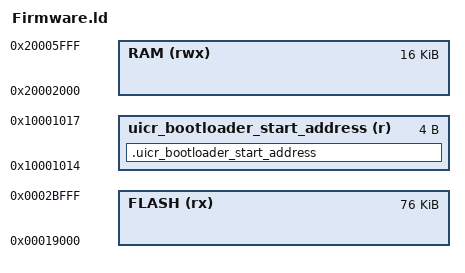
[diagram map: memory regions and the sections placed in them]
/* Linker script to configure memory regions. */

SEARCH_DIR(.)
GROUP(-lgcc -lc -lnosys)

/* More info about the memory layout here: */
/* https://infocenter.nordicsemi.com/topic/sdk_nrf5_v17.0.0/lib_bootloader.html#lib_bootloader_memory */
MEMORY
{
  /* We have 192 KB Flash (0x30000), 24 KB RAM (0x6000) */
  /* Softdevice uses pages from 0x0 to 0x18000 included */
  FLASH (rx) : ORIGIN = 0x19000, LENGTH = 0x13000 /* Total = 0x2C000 => max available memory in debug */
  RAM (rwx) :  ORIGIN = 0x20002000, LENGTH = 0x4000
  uicr_bootloader_start_address (r) : ORIGIN = 0x10001014, LENGTH = 0x4
}

SECTIONS
{
  .uicr_bootloader_start_address :
  {
    PROVIDE(__start_uicr_bootloader_start_address = .);
    KEEP(*(SORT(.uicr_bootloader_start_address*)))
    PROVIDE(__stop_uicr_bootloader_start_address = .);
  } > uicr_bootloader_start_address
}

SECTIONS
{
  . = ALIGN(4);
  .mem_section_dummy_ram :
  {
  }
  .cli_sorted_cmd_ptrs :
  {
    PROVIDE(__start_cli_sorted_cmd_ptrs = .);
    KEEP(*(.cli_sorted_cmd_ptrs))
    PROVIDE(__stop_cli_sorted_cmd_ptrs = .);
  } > RAM
  .fs_data :
  {
    PROVIDE(__start_fs_data = .);
    KEEP(*(.fs_data))
    PROVIDE(__stop_fs_data = .);
  } > RAM
  .log_dynamic_data :
  {
    PROVIDE(__start_log_dynamic_data = .);
    KEEP(*(SORT(.log_dynamic_data*)))
    PROVIDE(__stop_log_dynamic_data = .);
  } > RAM
  .log_filter_data :
  {
    PROVIDE(__start_log_filter_data = .);
    KEEP(*(SORT(.log_filter_data*)))
    PROVIDE(__stop_log_filter_data = .);
  } > RAM

} INSERT AFTER .data;

SECTIONS
{
  .mem_section_dummy_rom :
  {
  }
  .sdh_soc_observers :
  {
    PROVIDE(__start_sdh_soc_observers = .);
    KEEP(*(SORT(.sdh_soc_observers*)))
    PROVIDE(__stop_sdh_soc_observers = .);
  } > FLASH
  .sdh_stack_observers :
  {
    PROVIDE(__start_sdh_stack_observers = .);
    KEEP(*(SORT(.sdh_stack_observers*)))
    PROVIDE(__stop_sdh_stack_observers = .);
  } > FLASH
  .sdh_req_observers :
  {
    PROVIDE(__start_sdh_req_observers = .);
    KEEP(*(SORT(.sdh_req_observers*)))
    PROVIDE(__stop_sdh_req_observers = .);
  } > FLASH
  .sdh_state_observers :
  {
    PROVIDE(__start_sdh_state_observers = .);
    KEEP(*(SORT(.sdh_state_observers*)))
    PROVIDE(__stop_sdh_state_observers = .);
  } > FLASH
  .sdh_ble_observers :
  {
    PROVIDE(__start_sdh_ble_observers = .);
    KEEP(*(SORT(.sdh_ble_observers*)))
    PROVIDE(__stop_sdh_ble_observers = .);
  } > FLASH
  .pwr_mgmt_data :
  {
    PROVIDE(__start_pwr_mgmt_data = .);
    KEEP(*(SORT(.pwr_mgmt_data*)))
    PROVIDE(__stop_pwr_mgmt_data = .);
  } > FLASH
  .nrf_queue :
  {
    PROVIDE(__start_nrf_queue = .);
    KEEP(*(.nrf_queue))
    PROVIDE(__stop_nrf_queue = .);
  } > FLASH
  .log_const_data :
  {
    PROVIDE(__start_log_const_data = .);
    KEEP(*(SORT(.log_const_data*)))
    PROVIDE(__stop_log_const_data = .);
  } > FLASH
  .log_backends :
  {
    PROVIDE(__start_log_backends = .);
    KEEP(*(SORT(.log_backends*)))
    PROVIDE(__stop_log_backends = .);
  } > FLASH
  .nrf_balloc :
  {
    PROVIDE(__start_nrf_balloc = .);
    KEEP(*(.nrf_balloc))
    PROVIDE(__stop_nrf_balloc = .);
  } > FLASH

} INSERT AFTER .text

INCLUDE "nrf_common.ld"
